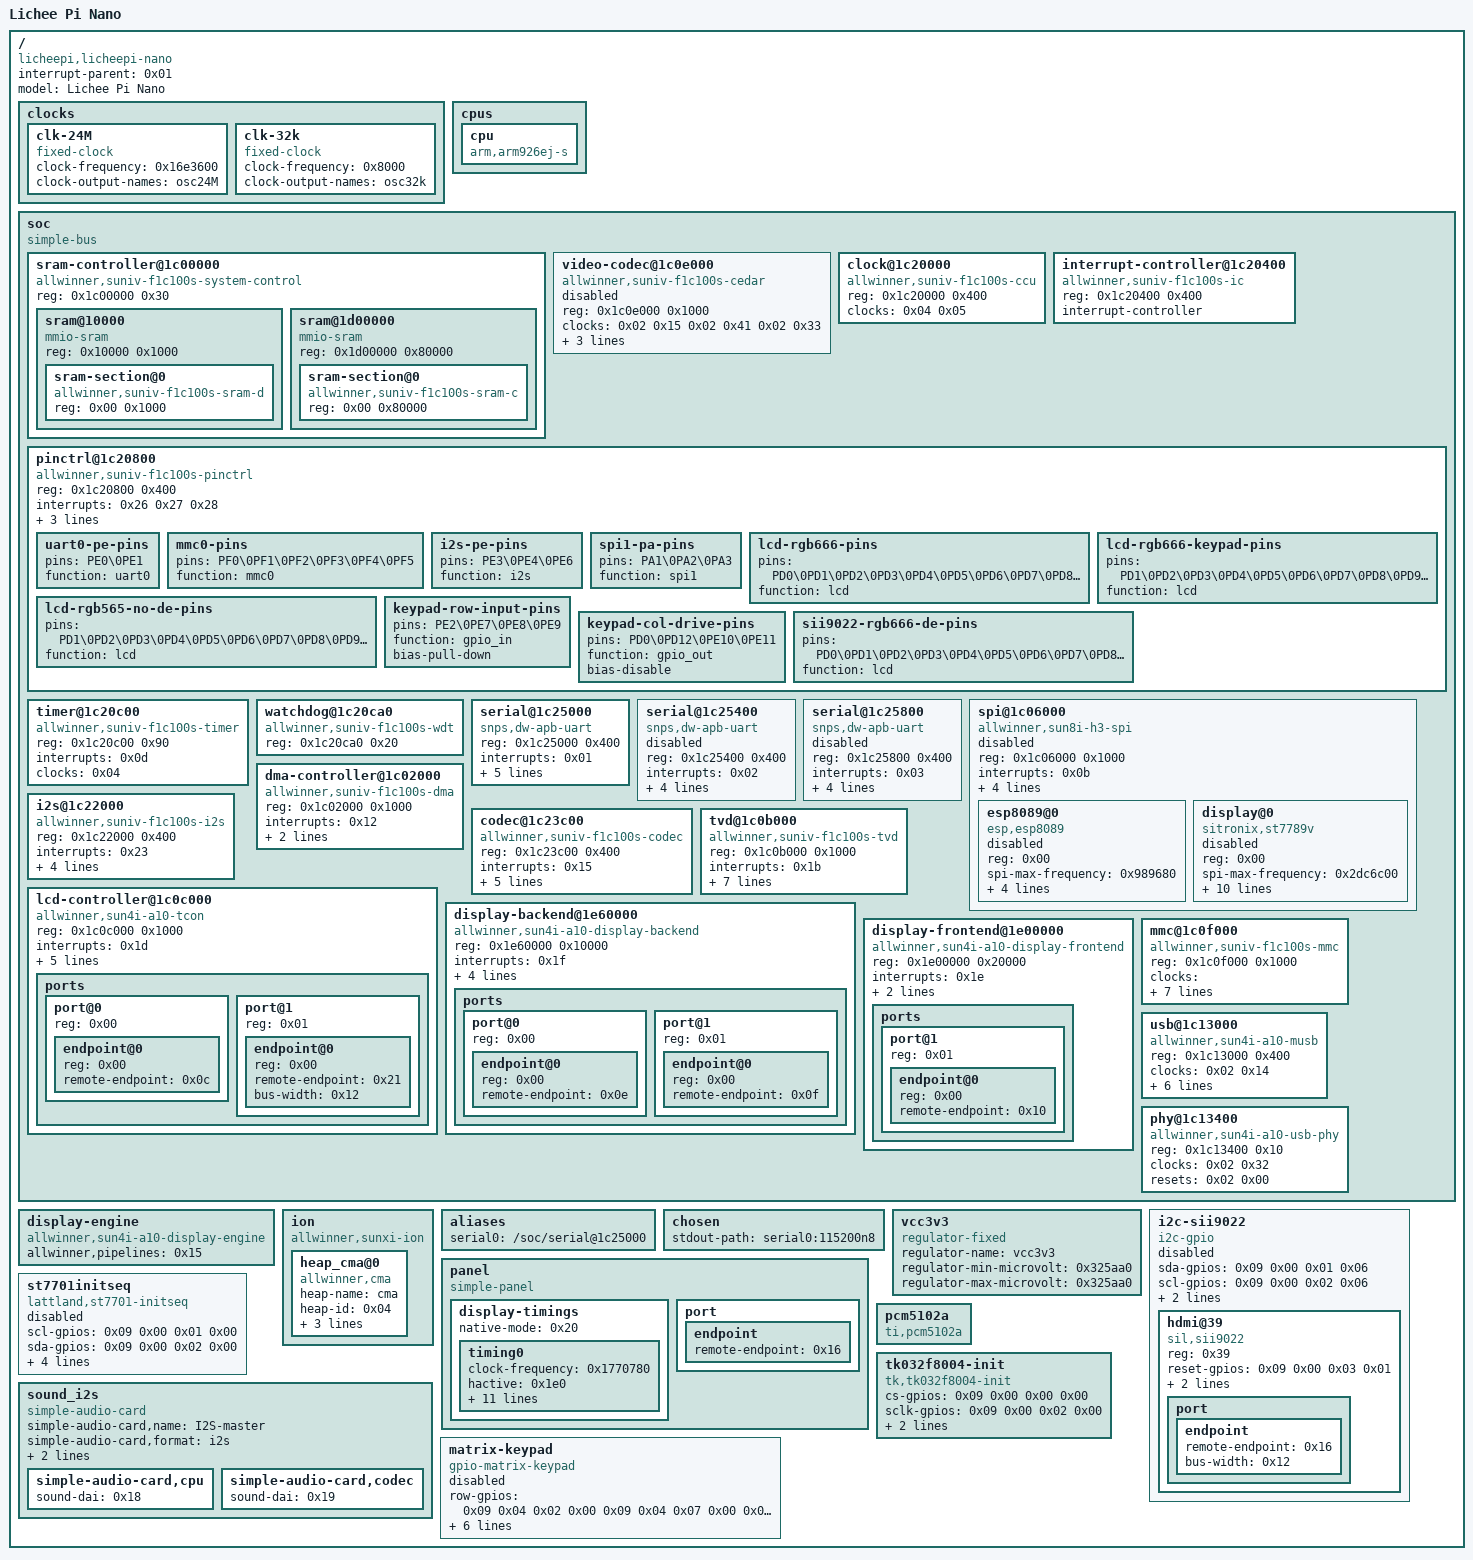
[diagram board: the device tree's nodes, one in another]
/dts-v1/;

/ {
	#address-cells = <0x01>;
	#size-cells = <0x01>;
	interrupt-parent = <0x01>;
	model = "Lichee Pi Nano";
	compatible = "licheepi,licheepi-nano\0allwinner,suniv-f1c100s";

	clocks {

		clk-24M {
			#clock-cells = <0x00>;
			compatible = "fixed-clock";
			clock-frequency = <0x16e3600>;
			clock-output-names = "osc24M";
			phandle = <0x04>;
		};

		clk-32k {
			#clock-cells = <0x00>;
			compatible = "fixed-clock";
			clock-frequency = <0x8000>;
			clock-output-names = "osc32k";
			phandle = <0x05>;
		};
	};

	cpus {

		cpu {
			compatible = "arm,arm926ej-s";
			device_type = "cpu";
		};
	};

	soc {
		compatible = "simple-bus";
		#address-cells = <0x01>;
		#size-cells = <0x01>;
		ranges;

		sram-controller@1c00000 {
			compatible = "allwinner,suniv-f1c100s-system-control\0allwinner,sun4i-a10-system-control";
			reg = <0x1c00000 0x30>;
			#address-cells = <0x01>;
			#size-cells = <0x01>;
			ranges;

			sram@10000 {
				compatible = "mmio-sram";
				reg = <0x10000 0x1000>;
				#address-cells = <0x01>;
				#size-cells = <0x01>;
				ranges = <0x00 0x10000 0x1000>;

				sram-section@0 {
					compatible = "allwinner,suniv-f1c100s-sram-d\0allwinner,sun4i-a10-sram-d";
					reg = <0x00 0x1000>;
					status = "okay";
					phandle = <0x14>;
				};
			};

			sram@1d00000 {
				compatible = "mmio-sram";
				reg = <0x1d00000 0x80000>;
				#address-cells = <0x01>;
				#size-cells = <0x01>;
				ranges = <0x00 0x1d00000 0x80000>;

				sram-section@0 {
					compatible = "allwinner,suniv-f1c100s-sram-c\0allwinner,sun4i-a10-sram-c1";
					reg = <0x00 0x80000>;
					phandle = <0x03>;
				};
			};
		};

		video-codec@1c0e000 {
			compatible = "allwinner,suniv-f1c100s-cedar";
			reg = <0x1c0e000 0x1000>;
			clocks = <0x02 0x15 0x02 0x41 0x02 0x33>;
			clock-names = "ahb\0mod\0ram";
			resets = <0x02 0x08>;
			interrupts = <0x22>;
			allwinner,sram = <0x03 0x01>;
			/* PA0/PA2/PA3 are reserved for the TK032F8004 init bus. */
			status = "disabled";
		};

		clock@1c20000 {
			compatible = "allwinner,suniv-f1c100s-ccu";
			reg = <0x1c20000 0x400>;
			clocks = <0x04 0x05>;
			clock-names = "hosc\0losc";
			#clock-cells = <0x01>;
			#reset-cells = <0x01>;
			phandle = <0x02>;
		};

		interrupt-controller@1c20400 {
			compatible = "allwinner,suniv-f1c100s-ic";
			reg = <0x1c20400 0x400>;
			interrupt-controller;
			#interrupt-cells = <0x01>;
			phandle = <0x01>;
		};

		pinctrl@1c20800 {
			compatible = "allwinner,suniv-f1c100s-pinctrl";
			reg = <0x1c20800 0x400>;
			interrupts = <0x26 0x27 0x28>;
			clocks = <0x02 0x25 0x04 0x05>;
			clock-names = "apb\0hosc\0losc";
			gpio-controller;
			interrupt-controller;
			#interrupt-cells = <0x03>;
			#gpio-cells = <0x03>;
			phandle = <0x09>;

			uart0-pe-pins {
				pins = "PE0\0PE1";
				function = "uart0";
				phandle = <0x06>;
			};

			mmc0-pins {
				pins = "PF0\0PF1\0PF2\0PF3\0PF4\0PF5";
				function = "mmc0";
				phandle = <0x11>;
			};

			i2s-pe-pins {
				pins = "PE3\0PE4\0PE6";
				function = "i2s";
				phandle = <0x0a>;
			};

			spi1-pa-pins {
				pins = "PA1\0PA2\0PA3";
				function = "spi1";
				phandle = <0x08>;
			};

			lcd-rgb666-pins {
				pins = "PD0\0PD1\0PD2\0PD3\0PD4\0PD5\0PD6\0PD7\0PD8\0PD9\0PD10\0PD11\0PD12\0PD13\0PD14\0PD15\0PD16\0PD17\0PD18\0PD20\0PD21";
				function = "lcd";
			};

			lcd-rgb666-keypad-pins {
				pins = "PD1\0PD2\0PD3\0PD4\0PD5\0PD6\0PD7\0PD8\0PD9\0PD10\0PD11\0PD13\0PD14\0PD15\0PD16\0PD17\0PD18\0PD20\0PD21";
				function = "lcd";
			};

			lcd-rgb565-no-de-pins {
				pins = "PD1\0PD2\0PD3\0PD4\0PD5\0PD6\0PD7\0PD8\0PD9\0PD10\0PD11\0PD13\0PD14\0PD15\0PD16\0PD17\0PD18\0PD20\0PD21";
				function = "lcd";
			};

			keypad-row-input-pins {
				pins = "PE2\0PE7\0PE8\0PE9";
				function = "gpio_in";
				bias-pull-down;
			};

			keypad-col-drive-pins {
				pins = "PD0\0PD12\0PE10\0PE11";
				function = "gpio_out";
				bias-disable;
			};

			sii9022-rgb666-de-pins {
				pins = "PD0\0PD1\0PD2\0PD3\0PD4\0PD5\0PD6\0PD7\0PD8\0PD9\0PD10\0PD11\0PD12\0PD13\0PD14\0PD15\0PD16\0PD17\0PD18\0PD19\0PD20\0PD21";
				function = "lcd";
				phandle = <0x0b>;
			};
		};

		timer@1c20c00 {
			compatible = "allwinner,suniv-f1c100s-timer";
			reg = <0x1c20c00 0x90>;
			interrupts = <0x0d>;
			clocks = <0x04>;
		};

		watchdog@1c20ca0 {
			compatible = "allwinner,suniv-f1c100s-wdt\0allwinner,sun6i-a31-wdt";
			reg = <0x1c20ca0 0x20>;
		};

		serial@1c25000 {
			compatible = "snps,dw-apb-uart";
			reg = <0x1c25000 0x400>;
			interrupts = <0x01>;
			reg-shift = <0x02>;
			reg-io-width = <0x04>;
			clocks = <0x02 0x26>;
			resets = <0x02 0x18>;
			status = "okay";
			pinctrl-names = "default";
			pinctrl-0 = <0x06>;
		};

		serial@1c25400 {
			compatible = "snps,dw-apb-uart";
			reg = <0x1c25400 0x400>;
			interrupts = <0x02>;
			reg-shift = <0x02>;
			reg-io-width = <0x04>;
			clocks = <0x02 0x27>;
			resets = <0x02 0x19>;
			status = "disabled";
		};

		serial@1c25800 {
			compatible = "snps,dw-apb-uart";
			reg = <0x1c25800 0x400>;
			interrupts = <0x03>;
			reg-shift = <0x02>;
			reg-io-width = <0x04>;
			clocks = <0x02 0x28>;
			resets = <0x02 0x1a>;
			status = "disabled";
		};

		spi@1c06000 {
			compatible = "allwinner,sun8i-h3-spi";
			reg = <0x1c06000 0x1000>;
			interrupts = <0x0b>;
			clocks = <0x02 0x13 0x02 0x13>;
			clock-names = "ahb\0mod";
			resets = <0x02 0x06>;
			dmas = <0x07 0x00 0x05 0x07 0x00 0x05>;
			dma-names = "rx\0tx";
			/* The panel owns PA0 (CS), PA2 (SCLK), PA1 (MOSI), and PA3 (MISO). */
			status = "disabled";
			#address-cells = <0x01>;
			#size-cells = <0x00>;
			pinctrl-names = "default";
			pinctrl-0 = <0x08>;

			esp8089@0 {
				compatible = "esp,esp8089";
				reg = <0x00>;
				status = "disabled";
				spi-max-frequency = <0x989680>;
				spi-cpol;
				spi-cpha;
				esp,poll-interval-ms = <0x01>;
				enable-gpios = <0x09 0x04 0x0c 0x00>;
			};

			display@0 {
				compatible = "sitronix,st7789v";
				reg = <0x00>;
				status = "disabled";
				spi-max-frequency = <0x2dc6c00>;
				spi-cpol;
				spi-cpha;
				buswidth = <0x08>;
				width = <0xf0>;
				height = <0x140>;
				rgb;
				rotate = <0x5a>;
				fps = <0x1e>;
				dc-gpios = <0x09 0x00 0x03 0x00>;
				reset-gpios = <0x09 0x00 0x00 0x01>;
			};
		};

		dma-controller@1c02000 {
			compatible = "allwinner,suniv-f1c100s-dma";
			reg = <0x1c02000 0x1000>;
			interrupts = <0x12>;
			clocks = <0x02 0x0e>;
			resets = <0x02 0x01>;
			#dma-cells = <0x02>;
			phandle = <0x07>;
		};

		i2s@1c22000 {
			#sound-dai-cells = <0x00>;
			compatible = "allwinner,suniv-f1c100s-i2s";
			reg = <0x1c22000 0x400>;
			interrupts = <0x23>;
			clocks = <0x02 0x21 0x02 0x2f>;
			clock-names = "apb\0mod";
			resets = <0x02 0x14>;
			dmas = <0x07 0x00 0x0e 0x07 0x00 0x0e>;
			dma-names = "rx\0tx";
			status = "okay";
			pinctrl-names = "default";
			pinctrl-0 = <0x0a>;
			phandle = <0x18>;
		};

		codec@1c23c00 {
			compatible = "allwinner,suniv-f1c100s-codec";
			reg = <0x1c23c00 0x400>;
			interrupts = <0x15>;
			clocks = <0x02 0x1d 0x02 0x42>;
			clock-names = "apb\0codec";
			resets = <0x02 0x10>;
			dmas = <0x07 0x00 0x0c 0x07 0x00 0x0c>;
			dma-names = "rx\0tx";
			status = "okay";
			allwinner,audio-routing = "Headphone\0HP\0Headphone\0HPCOM\0MIC\0Mic";
		};

		tvd@1c0b000 {
			compatible = "allwinner,suniv-f1c100s-tvd";
			reg = <0x1c0b000 0x1000>;
			interrupts = <0x1b>;
			clocks = <0x02 0x19 0x02 0x3f>;
			clock-names = "bus\0mod";
			resets = <0x02 0x0c>;
			reset-names = "bus";
			assigned-clocks = <0x02 0x3f>;
			assigned-clock-rates = <0x19bfcc0>;
			allwinner,input-channel = <0x00>;
			allwinner,default-standard = "ntsc";
			allwinner,blue-screen-mode = <0x02>;
			status = "okay";
		};

		lcd-controller@1c0c000 {
			compatible = "allwinner,sun4i-a10-tcon";
			reg = <0x1c0c000 0x1000>;
			interrupts = <0x1d>;
			clocks = <0x02 0x16 0x02 0x3b 0x04>;
			clock-names = "ahb\0tcon-ch0\0tcon-ch1";
			clock-output-names = "tcon-pixel-clock";
			resets = <0x02 0x09>;
			reset-names = "lcd";
			status = "okay";
			pinctrl-names = "default";
			pinctrl-0 = <0x0b>;
			srgn,swap-b-r;

			ports {
				#address-cells = <0x01>;
				#size-cells = <0x00>;

				port@0 {
					#address-cells = <0x01>;
					#size-cells = <0x00>;
					reg = <0x00>;

					endpoint@0 {
						reg = <0x00>;
						remote-endpoint = <0x0c>;
						phandle = <0x0f>;
					};
				};

				port@1 {
					#address-cells = <0x01>;
					#size-cells = <0x00>;
					reg = <0x01>;

					endpoint@0 {
						reg = <0x00>;
						remote-endpoint = <0x21>;
						bus-width = <0x12>;
						phandle = <0x16>;
					};
				};
			};
		};

		display-backend@1e60000 {
			compatible = "allwinner,sun4i-a10-display-backend";
			reg = <0x1e60000 0x10000>;
			reg-names = "be";
			interrupts = <0x1f>;
			clocks = <0x02 0x1b 0x02 0x39 0x02 0x38>;
			clock-names = "ahb\0mod\0ram";
			resets = <0x02 0x0e>;
			reset-names = "be";
			assigned-clocks = <0x02 0x39>;
			assigned-clock-rates = <0x11e1a300>;

			ports {
				#address-cells = <0x01>;
				#size-cells = <0x00>;

				port@0 {
					#address-cells = <0x01>;
					#size-cells = <0x00>;
					reg = <0x00>;

					endpoint@0 {
						reg = <0x00>;
						remote-endpoint = <0x0e>;
						phandle = <0x10>;
					};
				};

				port@1 {
					#address-cells = <0x01>;
					#size-cells = <0x00>;
					reg = <0x01>;

					endpoint@0 {
						reg = <0x00>;
						remote-endpoint = <0x0f>;
						phandle = <0x0c>;
					};
				};
			};
		};

		display-frontend@1e00000 {
			compatible = "allwinner,sun4i-a10-display-frontend";
			reg = <0x1e00000 0x20000>;
			interrupts = <0x1e>;
			clocks = <0x02 0x1c 0x02 0x3a 0x02 0x37>;
			clock-names = "ahb\0mod\0ram";
			resets = <0x02 0x0f>;
			status = "okay";
			phandle = <0x15>;

			ports {
				#address-cells = <0x01>;
				#size-cells = <0x00>;

				port@1 {
					#address-cells = <0x01>;
					#size-cells = <0x00>;
					reg = <0x01>;

					endpoint@0 {
						reg = <0x00>;
						remote-endpoint = <0x10>;
						phandle = <0x0e>;
					};
				};
			};
		};

		mmc@1c0f000 {
			compatible = "allwinner,suniv-f1c100s-mmc\0allwinner,sun7i-a20-mmc";
			reg = <0x1c0f000 0x1000>;
			clocks = <0x02 0x0f 0x02 0x29 0x02 0x2b 0x02 0x2a>;
			clock-names = "ahb\0mmc\0output\0sample";
			resets = <0x02 0x02>;
			reset-names = "ahb";
			interrupts = <0x17>;
			pinctrl-names = "default";
			pinctrl-0 = <0x11>;
			status = "okay";
			#address-cells = <0x01>;
			#size-cells = <0x00>;
			vmmc-supply = <0x12>;
			bus-width = <0x04>;
			broken-cd;
		};

		usb@1c13000 {
			compatible = "allwinner,sun4i-a10-musb";
			reg = <0x1c13000 0x400>;
			clocks = <0x02 0x14>;
			resets = <0x02 0x07>;
			interrupts = <0x1a>;
			interrupt-names = "mc";
			phys = <0x13 0x00>;
			phy-names = "usb";
			extcon = <0x13 0x00>;
			allwinner,sram = <0x14 0x01>;
			status = "okay";
			dr_mode = "host";
		};

		phy@1c13400 {
			compatible = "allwinner,sun4i-a10-usb-phy";
			reg = <0x1c13400 0x10>;
			reg-names = "phy_ctrl";
			clocks = <0x02 0x32>;
			clock-names = "usb0_phy";
			resets = <0x02 0x00>;
			reset-names = "usb0_reset";
			#phy-cells = <0x01>;
			status = "okay";
			phandle = <0x13>;
		};
	};

	display-engine {
		compatible = "allwinner,sun4i-a10-display-engine";
		allwinner,pipelines = <0x15>;
		status = "okay";
	};

	ion {
		compatible = "allwinner,sunxi-ion";
		status = "okay";

		heap_cma@0 {
			compatible = "allwinner,cma";
			heap-name = "cma";
			heap-id = <0x04>;
			heap-base = <0x00>;
			heap-size = <0x00>;
			heap-type = "ion_cma";
		};
	};

	aliases {
		serial0 = "/soc/serial@1c25000";
	};

	chosen {
		stdout-path = "serial0:115200n8";
	};

	vcc3v3 {
		compatible = "regulator-fixed";
		regulator-name = "vcc3v3";
		regulator-min-microvolt = <0x325aa0>;
		regulator-max-microvolt = <0x325aa0>;
		phandle = <0x12>;
	};

	i2c-sii9022 {
		compatible = "i2c-gpio";
		status = "disabled";
		sda-gpios = <0x09 0x00 0x01 0x06>;
		scl-gpios = <0x09 0x00 0x02 0x06>;
		i2c-gpio,sda-open-drain;
		i2c-gpio,scl-open-drain;
		#address-cells = <0x01>;
		#size-cells = <0x00>;

		hdmi@39 {
			compatible = "sil,sii9022";
			reg = <0x39>;
			reset-gpios = <0x09 0x00 0x03 0x01>;
			interrupt-parent = <0x09>;
			interrupts = <0x04 0x0c 0x01>;

			port {

				endpoint {
					remote-endpoint = <0x16>;
					bus-width = <0x12>;
					phandle = <0x0d>;
				};
			};
		};
	};

	panel {
		status = "okay";
		compatible = "simple-panel";
		#address-cells = <0x01>;
		#size-cells = <0x00>;

		display-timings {
			native-mode = <0x20>;
			timing0 {
				clock-frequency = <0x1770780>; /* 502 x 816 x 60 Hz */
				hactive = <0x1e0>;
				vactive = <0x320>;
				hfront-porch = <0x00>;
				hback-porch = <0x14>;
				hsync-len = <0x02>;
				vfront-porch = <0x00>;
				vback-porch = <0x09>;
				vsync-len = <0x07>;
				hsync-active = <0x00>;
				vsync-active = <0x00>;
				de-active = <0x01>;
				pixelclk-active = <0x00>;
				phandle = <0x20>;
			};
		};

		port {
			endpoint {
				remote-endpoint = <0x16>;
				phandle = <0x21>;
			};
		};
	};

	st7701initseq {
		compatible = "lattland,st7701-initseq";
		status = "disabled";
		scl-gpios = <0x09 0x00 0x01 0x00>;
		sda-gpios = <0x09 0x00 0x02 0x00>;
		cs-gpios = <0x09 0x00 0x00 0x00>;
		rst-gpios = <0x09 0x00 0x03 0x00>;
		init-sequence = <0x00 0x01 0xff 0x04 0x05 0x77 0x01 0x00 0x00 0x13 0x02 0xef 0x08 0x01 0xff 0x04 0x05 0x77 0x01 0x00 0x00 0x10 0x03 0xc0 0x4f 0x00 0x03 0xc1 0x07 0x02 0x03 0xc2 0x31 0x05 0x02 0xc7 0x04 0x01 0xc3 0x04 0x03 0x82 0x18 0x0e 0x02 0xcc 0x10 0x01 0xb0 0x04 0x10 0x0a 0x14 0x1b 0x0d 0x10 0x05 0x07 0x08 0x06 0x22 0x03 0x11 0x10 0xad 0x31 0x1b 0x01 0xb1 0x04 0x10 0x0a 0x14 0x1b 0x0d 0x10 0x05 0x07 0x08 0x06 0x22 0x03 0x11 0x10 0xad 0x31 0x1b 0x01 0xff 0x04 0x05 0x77 0x01 0x00 0x00 0x11 0x02 0xb0 0x53 0x02 0xb1 0x60 0x02 0xb2 0x07 0x02 0xb3 0x80 0x02 0xb5 0x49 0x02 0xb7 0x85 0x02 0xb8 0x21 0x02 0xc1 0x78 0x02 0xc2 0x78 0x01 0xe0 0x04 0x03 0x00 0x00 0x02 0x01 0xe1 0x04 0x0b 0x03 0xa0 0x00 0x00 0x02 0xa0 0x00 0x00 0x00 0x33 0x33 0x01 0xe2 0x04 0x0c 0x22 0x22 0x33 0x33 0x88 0xa0 0x00 0x00 0x87 0xa0 0x00 0x00 0x01 0xe3 0x04 0x04 0x00 0x00 0x22 0x22 0x03 0xe4 0x44 0x44 0x01 0xe5 0x04 0x10 0x04 0x84 0xa0 0xa0 0x06 0x86 0xa0 0xa0 0x08 0x88 0xa0 0xa0 0x0a 0x8a 0xa0 0xa0 0x01 0xe6 0x04 0x04 0x00 0x00 0x22 0x22 0x03 0xe7 0x44 0x44 0x01 0xe8 0x04 0x10 0x03 0x83 0xa0 0xa0 0x05 0x85 0xa0 0xa0 0x07 0x87 0xa0 0xa0 0x09 0x89 0xa0 0xa0 0x01 0xeb 0x04 0x07 0x00 0x01 0xe4 0xe4 0x88 0x00 0x40 0x03 0xec 0x3c 0x01 0x01 0xed 0x04 0x10 0xab 0x89 0x76 0x54 0x02 0xff 0xff 0xff 0xff 0xff 0xff 0x20 0x45 0x67 0x98 0xba 0x02 0x36 0x10 0x01 0xff 0x04 0x05 0x77 0x01 0x00 0x00 0x13 0x03 0xe8 0x00 0x0e 0x01 0x20 0x02 0x3a 0x50 0x01 0x11 0x05 0x06 0x96 0x00 0x03 0xe8 0x00 0x0c 0x05 0x06 0x64 0x00 0x03 0xe8 0x00 0x00 0x01 0xff 0x04 0x05 0x77 0x01 0x00 0x00 0x00 0x01 0x29 0x05 0x06 0x14>;
	};

	pcm5102a {
		#sound-dai-cells = <0x00>;
		compatible = "ti,pcm5102a";
		status = "okay";
		phandle = <0x19>;
	};

	sound_i2s {
		compatible = "simple-audio-card";
		simple-audio-card,name = "I2S-master";
		simple-audio-card,format = "i2s";
		simple-audio-card,bitclock-master = <0x17>;
		simple-audio-card,frame-master = <0x17>;
		status = "okay";

		simple-audio-card,cpu {
			sound-dai = <0x18>;
			phandle = <0x17>;
		};

		simple-audio-card,codec {
			sound-dai = <0x19>;
		};
	};

	matrix-keypad {
		compatible = "gpio-matrix-keypad";
		row-gpios = <0x09 0x04 0x02 0x00 0x09 0x04 0x07 0x00 0x09 0x04 0x08 0x00 0x09 0x04 0x09 0x00>;
		col-gpios = <0x09 0x03 0x00 0x00 0x09 0x03 0x0c 0x00 0x09 0x04 0x0a 0x00 0x09 0x04 0x0b 0x00>;
		col-scan-delay-us = <0x1388>;
		debounce-delay-ms = <0x0a>;
		linux,keymap = <0x1e 0x10015 0x2002d 0x30030 0x100001c 0x103000f 0x200006a 0x2010067 0x2020069 0x203006c 0x3000068 0x3010066 0x302006d 0x303006b>;
		status = "disabled";
	};

	tk032f8004-init {
		compatible = "tk,tk032f8004-init";
		status = "okay";
		cs-gpios = <0x09 0x00 0x00 0x00>;
		sclk-gpios = <0x09 0x00 0x02 0x00>;
		mosi-gpios = <0x09 0x00 0x01 0x00>;
		miso-gpios = <0x09 0x00 0x03 0x00>;
	};
};
